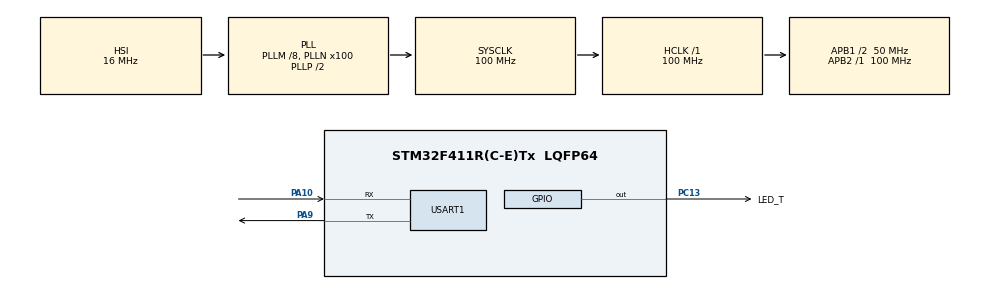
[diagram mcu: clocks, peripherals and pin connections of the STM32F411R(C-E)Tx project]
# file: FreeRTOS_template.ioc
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FREERTOS.BinarySemaphores01=KeyBinarySem01,Dynamic,NULL
FREERTOS.Tasks01=defaultTask,8,128,StartDefaultTask,Default,NULL,Dynamic,NULL,NULL;key_task,9,128,KeyTaskFunc,Default,NULL,Dynamic,NULL,NULL;Log_Task,9,128,LogTaskFunc,Default,NULL,Dynamic,NULL,NULL
Mcu.Family=STM32F4
Mcu.Name=STM32F411R(C-E)Tx
Mcu.Package=LQFP64
NVIC.PriorityGroup=NVIC_PRIORITYGROUP_4
NVIC.TIM1_TRG_COM_TIM11_IRQn=true\:15\:0\:false\:false\:true\:false\:false\:true\:true
NVIC.TimeBase=TIM1_TRG_COM_TIM11_IRQn
NVIC.TimeBaseIP=TIM11
PA10.Mode=Asynchronous
PA10.Signal=USART1_RX
PA13.Mode=Serial_Wire
PA13.Signal=SYS_JTMS-SWDIO
PA14.Mode=Serial_Wire
PA14.Signal=SYS_JTCK-SWCLK
PA9.Mode=Asynchronous
PA9.Signal=USART1_TX
PC13-ANTI_TAMP.GPIO_Label=LED_T
PC13-ANTI_TAMP.Signal=GPIO_Output
PC14-OSC32_IN.Mode=LSE-External-Oscillator
PC14-OSC32_IN.Signal=RCC_OSC32_IN
PC15-OSC32_OUT.Mode=LSE-External-Oscillator
PC15-OSC32_OUT.Signal=RCC_OSC32_OUT
PH0\ -\ OSC_IN.Mode=HSE-External-Oscillator
PH0\ -\ OSC_IN.Signal=RCC_OSC_IN
PH1\ -\ OSC_OUT.Mode=HSE-External-Oscillator
PH1\ -\ OSC_OUT.Signal=RCC_OSC_OUT
ProjectManager.HeapSize=0x200
ProjectManager.StackSize=0x400
ProjectManager.TargetToolchain=MDK-ARM V5.32
RCC.48MHZClocksFreq_Value=50000000
RCC.AHBFreq_Value=100000000
RCC.APB1CLKDivider=RCC_HCLK_DIV2
RCC.APB1Freq_Value=50000000
RCC.APB1TimFreq_Value=100000000
RCC.APB2Freq_Value=100000000
RCC.APB2TimFreq_Value=100000000
RCC.CortexFreq_Value=100000000
RCC.HCLKFreq_Value=100000000
RCC.HSE_VALUE=25000000
RCC.HSI_VALUE=16000000
RCC.PLLM=8
RCC.PLLN=100
RCC.SYSCLKFreq_VALUE=100000000
RCC.SYSCLKSource=RCC_SYSCLKSOURCE_PLLCLK
RCC.VCOOutputFreq_Value=200000000
USART1.VirtualMode=VM_ASYNC
VP_FREERTOS_VS_CMSIS_V2.Mode=CMSIS_V2
VP_SYS_VS_tim11.Mode=TIM11
board=custom

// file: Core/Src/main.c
/* USER CODE BEGIN Header */
/**
  ******************************************************************************
  * @file           : main.c
  * @brief          : Main program body
  ******************************************************************************
  * @attention
  *
  * Copyright (c) 2023 STMicroelectronics.
  * All rights reserved.
  *
  * This software is licensed under terms that can be found in the LICENSE file
  * in the root directory of this software component.
  * If no LICENSE file comes with this software, it is provided AS-IS.
  *
  ******************************************************************************
  */
/* USER CODE END Header */
#include "main.h"
#include "cmsis_os.h"
#include "usart.h"
#include "gpio.h"

/* USER CODE BEGIN Includes */
#include "key.h"
/* USER CODE END Includes */

/* USER CODE BEGIN PV */
uint32_t FreeRTOSRunTimeTicks;
void ConfigureTimerForRunTimeStats(void)
{
	FreeRTOSRunTimeTicks = 0;
}
/* USER CODE END PV */

void SystemClock_Config(void);
void MX_FREERTOS_Init(void);

int main(void)
{

  /* MCU Configuration--------------------------------------------------------*/

  /* Reset of all peripherals, Initializes the Flash interface and the Systick. */
  HAL_Init();

  /* Configure the system clock */
  SystemClock_Config();

  /* Initialize all configured peripherals */
  MX_GPIO_Init();
  MX_USART1_UART_Init();
  /* USER CODE BEGIN 2 */

	Key_Port_Init();

  /* USER CODE END 2 */

  /* Init scheduler */
  osKernelInitialize();  /* Call init function for freertos objects (in freertos.c) */
  MX_FREERTOS_Init();

  /* Start scheduler */
  osKernelStart();

  /* We should never get here as control is now taken by the scheduler */
  /* Infinite loop */
  while (1)
  {

  }
}

void SystemClock_Config(void)
{
  RCC_OscInitTypeDef RCC_OscInitStruct = {0};
  RCC_ClkInitTypeDef RCC_ClkInitStruct = {0};

  /** Configure the main internal regulator output voltage
  */
  __HAL_RCC_PWR_CLK_ENABLE();
  __HAL_PWR_VOLTAGESCALING_CONFIG(PWR_REGULATOR_VOLTAGE_SCALE1);

  /** Initializes the RCC Oscillators according to the specified parameters
  * in the RCC_OscInitTypeDef structure.
  */
  RCC_OscInitStruct.OscillatorType = RCC_OSCILLATORTYPE_HSI;
  RCC_OscInitStruct.HSIState = RCC_HSI_ON;
  RCC_OscInitStruct.HSICalibrationValue = RCC_HSICALIBRATION_DEFAULT;
  RCC_OscInitStruct.PLL.PLLState = RCC_PLL_ON;
  RCC_OscInitStruct.PLL.PLLSource = RCC_PLLSOURCE_HSI;
  RCC_OscInitStruct.PLL.PLLM = 8;
  RCC_OscInitStruct.PLL.PLLN = 100;
  RCC_OscInitStruct.PLL.PLLP = RCC_PLLP_DIV2;
  RCC_OscInitStruct.PLL.PLLQ = 4;
  if (HAL_RCC_OscConfig(&RCC_OscInitStruct) != HAL_OK)
  {
    Error_Handler();
  }

  /** Initializes the CPU, AHB and APB buses clocks
  */
  RCC_ClkInitStruct.ClockType = RCC_CLOCKTYPE_HCLK|RCC_CLOCKTYPE_SYSCLK
                              |RCC_CLOCKTYPE_PCLK1|RCC_CLOCKTYPE_PCLK2;
  RCC_ClkInitStruct.SYSCLKSource = RCC_SYSCLKSOURCE_PLLCLK;
  RCC_ClkInitStruct.AHBCLKDivider = RCC_SYSCLK_DIV1;
  RCC_ClkInitStruct.APB1CLKDivider = RCC_HCLK_DIV2;
  RCC_ClkInitStruct.APB2CLKDivider = RCC_HCLK_DIV1;

  if (HAL_RCC_ClockConfig(&RCC_ClkInitStruct, FLASH_LATENCY_3) != HAL_OK)
  {
    Error_Handler();
  }
}

void HAL_TIM_PeriodElapsedCallback(TIM_HandleTypeDef *htim)
{
  if (htim->Instance == TIM11) {
    HAL_IncTick();
  }
}

void Error_Handler(void)
{
  __disable_irq();
  while (1)
  {
  }
}

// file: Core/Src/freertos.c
/* USER CODE BEGIN Header */
/**
  ******************************************************************************
  * File Name          : freertos.c
  * Description        : Code for freertos applications
  ******************************************************************************
  * @attention
  *
  * Copyright (c) 2023 STMicroelectronics.
  * All rights reserved.
  *
  * This software is licensed under terms that can be found in the LICENSE file
  * in the root directory of this software component.
  * If no LICENSE file comes with this software, it is provided AS-IS.
  *
  ******************************************************************************
  */
/* USER CODE END Header */

#include "FreeRTOS.h"
#include "task.h"
#include "main.h"
#include "cmsis_os.h"

/* USER CODE BEGIN Includes */
#include <stdio.h>
#include "key.h"
/* USER CODE END Includes */

/* Definitions for defaultTask */
osThreadId_t defaultTaskHandle;
const osThreadAttr_t defaultTask_attributes = {
  .name = "defaultTask",
  .stack_size = 128 * 4,
  .priority = (osPriority_t) osPriorityLow,
};
/* Definitions for key_task */
osThreadId_t key_taskHandle;
const osThreadAttr_t key_task_attributes = {
  .name = "key_task",
  .stack_size = 128 * 4,
  .priority = (osPriority_t) osPriorityLow1,
};
/* Definitions for Log_Task */
osThreadId_t Log_TaskHandle;
const osThreadAttr_t Log_Task_attributes = {
  .name = "Log_Task",
  .stack_size = 128 * 4,
  .priority = (osPriority_t) osPriorityLow1,
};
/* Definitions for KeyBinarySem01 */
osSemaphoreId_t KeyBinarySem01Handle;
const osSemaphoreAttr_t KeyBinarySem01_attributes = {
  .name = "KeyBinarySem01"
};

void StartDefaultTask(void *argument);
void KeyTaskFunc(void *argument);
void LogTaskFunc(void *argument);

void MX_FREERTOS_Init(void); /* (MISRA C 2004 rule 8.1) */

void MX_FREERTOS_Init(void) {

  /* Create the semaphores(s) */
  /* creation of KeyBinarySem01 */
  KeyBinarySem01Handle = osSemaphoreNew(1, 1, &KeyBinarySem01_attributes);

  /* Create the thread(s) */
  /* creation of defaultTask */
  defaultTaskHandle = osThreadNew(StartDefaultTask, NULL, &defaultTask_attributes);

  /* creation of key_task */
  key_taskHandle = osThreadNew(KeyTaskFunc, NULL, &key_task_attributes);

  /* creation of Log_Task */
  Log_TaskHandle = osThreadNew(LogTaskFunc, NULL, &Log_Task_attributes);

}

void StartDefaultTask(void *argument)
{
  /* USER CODE BEGIN StartDefaultTask */
  /* Infinite loop */
  for(;;)
  {
		HAL_GPIO_TogglePin(LED_T_GPIO_Port, LED_T_Pin);
    osDelay(500);
  }
  /* USER CODE END StartDefaultTask */
}

void KeyTaskFunc(void *argument)
{
  /* USER CODE BEGIN KeyTaskFunc */
  /* Infinite loop */
  for(;;)
  {
		if(KeyScan(0))
		{
			osSemaphoreRelease(KeyBinarySem01Handle);
		}
    osDelay(1);
  }
  /* USER CODE END KeyTaskFunc */
}

void LogTaskFunc(void *argument)
{
  /* USER CODE BEGIN LogTaskFunc */
  /* Infinite loop */
  for(;;)
  {
		// infinite wait
		if(osSemaphoreAcquire(KeyBinarySem01Handle, 100) == osOK)
			printf("key pressed\r\n");
    osDelay(500);
  }
  /* USER CODE END LogTaskFunc */
}
